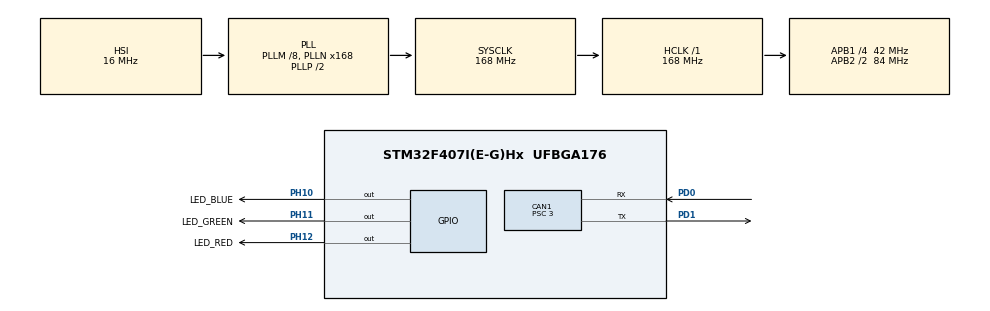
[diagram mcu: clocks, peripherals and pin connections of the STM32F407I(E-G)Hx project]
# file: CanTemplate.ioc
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CAN1.BS1=CAN_BS1_9TQ
CAN1.BS2=CAN_BS2_4TQ
CAN1.CalculateBaudRate=1000000
CAN1.CalculateTimeBit=1000
CAN1.CalculateTimeQuantum=71.42857142857143
CAN1.Prescaler=3
Mcu.Family=STM32F4
Mcu.Name=STM32F407I(E-G)Hx
Mcu.Package=UFBGA176
NVIC.CAN1_RX0_IRQn=true\:0\:0\:false\:false\:true\:true\:true\:true
NVIC.CAN1_TX_IRQn=true\:0\:0\:false\:false\:true\:true\:true\:true
NVIC.PriorityGroup=NVIC_PRIORITYGROUP_4
NVIC.TIM2_IRQn=true\:0\:0\:false\:false\:true\:true\:true\:true
NVIC.TIM3_IRQn=true\:0\:0\:false\:false\:true\:true\:true\:true
PA13.Mode=Serial_Wire
PA13.Signal=SYS_JTMS-SWDIO
PA14.Mode=Serial_Wire
PA14.Signal=SYS_JTCK-SWCLK
PD0.Mode=CAN_Activate
PD0.Signal=CAN1_RX
PD1.Mode=CAN_Activate
PD1.Signal=CAN1_TX
PH0-OSC_IN.Mode=HSE-External-Oscillator
PH0-OSC_IN.Signal=RCC_OSC_IN
PH1-OSC_OUT.Mode=HSE-External-Oscillator
PH1-OSC_OUT.Signal=RCC_OSC_OUT
PH10.GPIO_Label=LED_BLUE
PH10.Signal=GPIO_Output
PH11.GPIO_Label=LED_GREEN
PH11.Signal=GPIO_Output
PH12.GPIO_Label=LED_RED
PH12.Signal=GPIO_Output
ProjectManager.HeapSize=0x200
ProjectManager.StackSize=0x400
ProjectManager.TargetToolchain=CMake
RCC.48MHZClocksFreq_Value=84000000
RCC.AHBFreq_Value=168000000
RCC.APB1CLKDivider=RCC_HCLK_DIV4
RCC.APB1Freq_Value=42000000
RCC.APB1TimFreq_Value=84000000
RCC.APB2CLKDivider=RCC_HCLK_DIV2
RCC.APB2Freq_Value=84000000
RCC.APB2TimFreq_Value=168000000
RCC.CortexFreq_Value=168000000
RCC.HCLKFreq_Value=168000000
RCC.HSE_VALUE=25000000
RCC.HSI_VALUE=16000000
RCC.LSE_VALUE=32768
RCC.PLLM=8
RCC.PLLN=168
RCC.SYSCLKFreq_VALUE=168000000
RCC.SYSCLKSource=RCC_SYSCLKSOURCE_PLLCLK
RCC.VCOOutputFreq_Value=336000000
TIM2.Period=999
TIM2.Prescaler=167
TIM3.Period=999
TIM3.Prescaler=167
VP_TIM2_VS_ClockSourceINT.Mode=Internal
VP_TIM3_VS_ClockSourceINT.Mode=Internal
board=custom

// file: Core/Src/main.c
/* USER CODE BEGIN Header */
/**
 ******************************************************************************
 * @file           : main.c
 * @brief          : Main program body
 ******************************************************************************
 * @attention
 *
 * Copyright (c) 2025 STMicroelectronics.
 * All rights reserved.
 *
 * This software is licensed under terms that can be found in the LICENSE file
 * in the root directory of this software component.
 * If no LICENSE file comes with this software, it is provided AS-IS.
 *
 ******************************************************************************
 */
/* USER CODE END Header */
#include "main.h"
#include "can.h"
#include "gpio.h"
#include "tim.h"

/* USER CODE BEGIN Includes */
#include "App.hpp"
#include "CanTemplate.hpp"

/* USER CODE END Includes */

void SystemClock_Config(void);
/* USER CODE BEGIN PFP */

// 定时器中断回调函数开启接受发送
void HAL_TIM_PeriodElapsedCallback(TIM_HandleTypeDef *htim)
{
    if (htim == &htim2) {
        getCanData();
    }
    if (htim == &htim3) {
        sendCanData();
    }
}
/* USER CODE END PFP */

int main(void) {

  /* MCU Configuration--------------------------------------------------------*/

  /* Reset of all peripherals, Initializes the Flash interface and the Systick.
   */
  HAL_Init();

  /* Configure the system clock */
  SystemClock_Config();

  /* Initialize all configured peripherals */
  MX_GPIO_Init();
  MX_CAN1_Init();
  MX_TIM2_Init();
  MX_TIM3_Init();
  /* USER CODE BEGIN 2 */
  HAL_TIM_Base_Start_IT(&htim2);
  HAL_TIM_Base_Start_IT(&htim3);

  initCanTemplate();

  /* USER CODE END 2 */

  /* Infinite loop */
  while (1) {

  }
}

void SystemClock_Config(void) {
  RCC_OscInitTypeDef RCC_OscInitStruct = {0};
  RCC_ClkInitTypeDef RCC_ClkInitStruct = {0};

  /** Configure the main internal regulator output voltage
   */
  __HAL_RCC_PWR_CLK_ENABLE();
  __HAL_PWR_VOLTAGESCALING_CONFIG(PWR_REGULATOR_VOLTAGE_SCALE1);

  /** Initializes the RCC Oscillators according to the specified parameters
   * in the RCC_OscInitTypeDef structure.
   */
  RCC_OscInitStruct.OscillatorType = RCC_OSCILLATORTYPE_HSI;
  RCC_OscInitStruct.HSIState = RCC_HSI_ON;
  RCC_OscInitStruct.HSICalibrationValue = RCC_HSICALIBRATION_DEFAULT;
  RCC_OscInitStruct.PLL.PLLState = RCC_PLL_ON;
  RCC_OscInitStruct.PLL.PLLSource = RCC_PLLSOURCE_HSI;
  RCC_OscInitStruct.PLL.PLLM = 8;
  RCC_OscInitStruct.PLL.PLLN = 168;
  RCC_OscInitStruct.PLL.PLLP = RCC_PLLP_DIV2;
  RCC_OscInitStruct.PLL.PLLQ = 4;
  if (HAL_RCC_OscConfig(&RCC_OscInitStruct) != HAL_OK) {
    Error_Handler();
  }

  /** Initializes the CPU, AHB and APB buses clocks
   */
  RCC_ClkInitStruct.ClockType = RCC_CLOCKTYPE_HCLK | RCC_CLOCKTYPE_SYSCLK |
                                RCC_CLOCKTYPE_PCLK1 | RCC_CLOCKTYPE_PCLK2;
  RCC_ClkInitStruct.SYSCLKSource = RCC_SYSCLKSOURCE_PLLCLK;
  RCC_ClkInitStruct.AHBCLKDivider = RCC_SYSCLK_DIV1;
  RCC_ClkInitStruct.APB1CLKDivider = RCC_HCLK_DIV4;
  RCC_ClkInitStruct.APB2CLKDivider = RCC_HCLK_DIV2;

  if (HAL_RCC_ClockConfig(&RCC_ClkInitStruct, FLASH_LATENCY_5) != HAL_OK) {
    Error_Handler();
  }
}

/* USER CODE BEGIN 4 */
// void HAL_TIM_PeriodElapsedCallback(TIM_HandleTypeDef *htim) {
//   if (htim == &htim2) {
//     getCanData();
//   }
//   if (htim == &htim3) {
//     sendCanData();
//   }
// }
/* USER CODE END 4 */

void Error_Handler(void) {
  __disable_irq();
  while (1) {
  }
}

#ifdef USE_FULL_ASSERT
/**
 * @brief  Reports the name of the source file and the source line number
 *         where the assert_param error has occurred.
 * @param  file: pointer to the source file name
 * @param  line: assert_param error line source number
 * @retval None
 */
void assert_failed(uint8_t *file, uint32_t line) {
  /* USER CODE BEGIN 6 */
  /* User can add his own implementation to report the file name and line
     number, ex: printf("Wrong parameters value: file %s on line %d\r\n", file,
     line) */
  /* USER CODE END 6 */
}
#endif /* USE_FULL_ASSERT */
